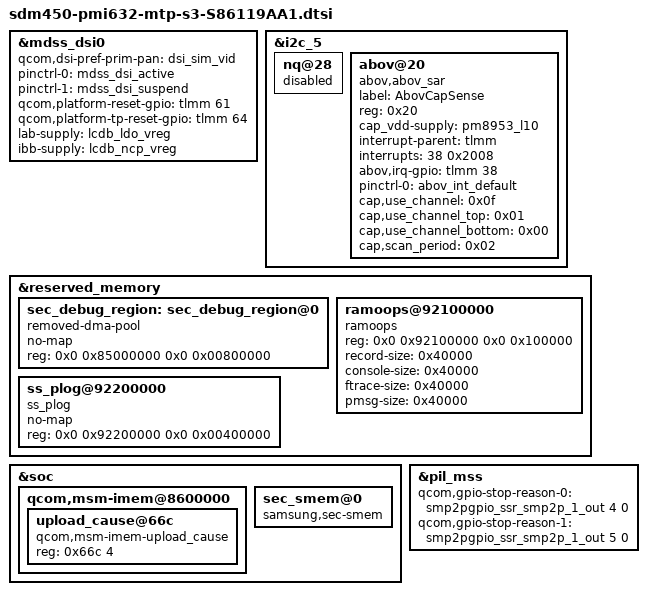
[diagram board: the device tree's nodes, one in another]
/*
 * Copyright (c) 2018, The Linux Foundation. All rights reserved.
 *
 * This program is free software; you can redistribute it and/or modify
 * it under the terms of the GNU General Public License version 2 and
 * only version 2 as published by the Free Software Foundation.
 *
 * This program is distributed in the hope that it will be useful,
 * but WITHOUT ANY WARRANTY; without even the implied warranty of
 * MERCHANTABILITY or FITNESS FOR A PARTICULAR PURPOSE.  See the
 * GNU General Public License for more details.
 */

#include "msm8953-mtp.dtsi"

/*
&eeprom0 {
	cam_vdig-supply = <&pm8953_l23>;
};

&camera0 {
	cam_vdig-supply = <&pm8953_l23>;
};*/

&mdss_dsi0 {
	qcom,dsi-pref-prim-pan = <&dsi_sim_vid>;
	pinctrl-names = "mdss_default", "mdss_sleep";
	pinctrl-0 = <&mdss_dsi_active>;
	pinctrl-1 = <&mdss_dsi_suspend>;
	qcom,platform-reset-gpio = <&tlmm 61 0>;
	qcom,platform-tp-reset-gpio = <&tlmm 64 0>;
	// qcom,platform-bklight-en-gpio = <&pm8953_gpios 4 0>;
	lab-supply = <&lcdb_ldo_vreg>;
	ibb-supply = <&lcdb_ncp_vreg>;

};

/*+Bug 440975 lishuai_wt,20190501,add,open sar sensor for sda450*/
&i2c_5 { /* BLSP2 QUP1 */
	status = "ok";
	nq@28 {
		status = "disabled";
	};
	abov@20 {
		label = "AbovCapSense";
		compatible = "abov,abov_sar";
		reg = <0x20>;
		cap_vdd-supply = <&pm8953_l10>;
		interrupt-parent = <&tlmm>;
		interrupts = <38 0x2008>;
		abov,irq-gpio = <&tlmm 38 0x2008>; /* IRQ */
		pinctrl-names = "abov_int_default";
		pinctrl-0 = <&abov_int_default>;
		cap,use_channel = <0x0f>;
		cap,use_channel_top = <0x01>;
		cap,use_channel_bottom = <0x00>;
		cap,scan_period = <0x02>;

	};
};
/*-Bug 440975 lishuai_wt,20190501,add,open sar sensor for sda450*/

/* Samsung SEC_DEBUG */
&reserved_memory {
	/* CONFIG_SEC_DEBUG reserves 8MB */
	sec_debug_region: sec_debug_region@0 {
		  compatible = "removed-dma-pool";
		  no-map;
		reg = <0x0 0x85000000 0x0 0x00800000>;
	};

	ramoops@92100000 {
		  compatible = "ramoops";
		  reg = <0x0 0x92100000 0x0 0x100000>;
		  record-size = <0x40000>;
		  console-size = <0x40000>;
		  ftrace-size = <0x40000>;
		  pmsg-size = <0x40000>;
	};

	ss_plog@92200000 {
		compatible = "ss_plog";
		no-map;
		reg = <0x0 0x92200000 0x0 0x00400000>;
	};
};

&soc {
	qcom,msm-imem@8600000 {
		upload_cause@66c {
			compatible = "qcom,msm-imem-upload_cause";
			reg = <0x66c 4>;
		};
	};
	sec_smem@0 {
		compatible = "samsung,sec-smem";
		status = "okay";
	};
};

&pil_mss {
	/* GPIO output to mss */
	qcom,gpio-stop-reason-0 = <&smp2pgpio_ssr_smp2p_1_out 4 0>;
	qcom,gpio-stop-reason-1 = <&smp2pgpio_ssr_smp2p_1_out 5 0>;
};
